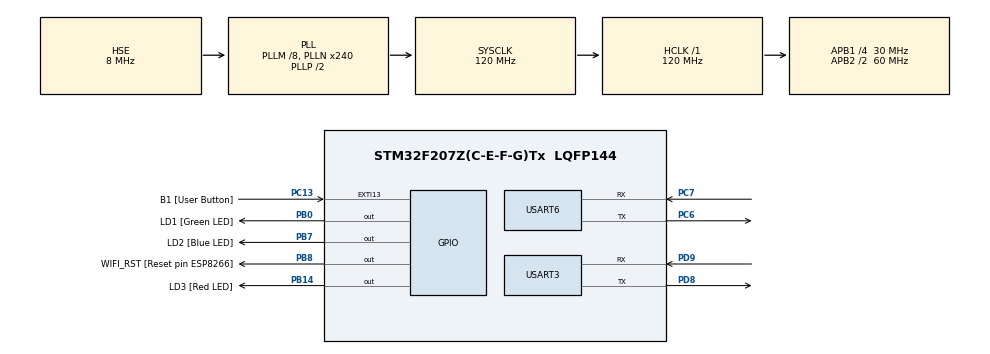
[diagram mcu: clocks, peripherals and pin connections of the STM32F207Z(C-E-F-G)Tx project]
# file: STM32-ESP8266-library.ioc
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FREERTOS.INCLUDE_vTaskCleanUpResources=1
FREERTOS.INCLUDE_vTaskDelayUntil=1
FREERTOS.Tasks01=DLMSThread,0,1280,DLMSThread_fun,Default,NULL,Dynamic,NULL,NULL
FREERTOS.configCHECK_FOR_STACK_OVERFLOW=1
FREERTOS.configMAX_PRIORITIES=8
FREERTOS.configTOTAL_HEAP_SIZE=65536
FREERTOS.configUSE_COUNTING_SEMAPHORES=1
FREERTOS.configUSE_MALLOC_FAILED_HOOK=1
FREERTOS.configUSE_NEWLIB_REENTRANT=1
FREERTOS.configUSE_RECURSIVE_MUTEXES=1
FREERTOS.configUSE_TIMERS=1
FREERTOS.configUSE_TRACE_FACILITY=1
Mcu.Family=STM32F2
Mcu.Name=STM32F207Z(C-E-F-G)Tx
Mcu.Package=LQFP144
Mcu.UserConstants=configMESSAGE_BUFFER_LENGTH_TYPE,size_t
NVIC.PriorityGroup=NVIC_PRIORITYGROUP_4
NVIC.TIM1_UP_TIM10_IRQn=true\:5\:0\:false\:false\:true\:false\:false\:true\:true
NVIC.TimeBase=TIM1_UP_TIM10_IRQn
NVIC.TimeBaseIP=TIM1
NVIC.USART3_IRQn=true\:5\:0\:true\:false\:true\:true\:true\:true\:true
NVIC.USART6_IRQn=true\:14\:0\:true\:false\:true\:true\:true\:true\:true
PA13.Mode=Serial_Wire
PA13.Signal=SYS_JTMS-SWDIO
PA14.Mode=Serial_Wire
PA14.Signal=SYS_JTCK-SWCLK
PB0.GPIO_Label=LD1 [Green LED]
PB0.Signal=GPIO_Output
PB14.GPIO_Label=LD3 [Red LED]
PB14.Signal=GPIO_Output
PB7.GPIO_Label=LD2 [Blue LED]
PB7.Signal=GPIO_Output
PB8.GPIO_Label=WIFI_RST [Reset pin ESP8266]
PB8.GPIO_PuPd=GPIO_PULLUP
PB8.PinState=GPIO_PIN_SET
PB8.Signal=GPIO_Output
PC13.GPIO_Label=B1 [User Button]
PC13.GPIO_ModeDefaultEXTI=GPIO_MODE_IT_FALLING
PC13.Signal=GPXTI13
PC14-OSC32_IN.Mode=LSE-External-Oscillator
PC14-OSC32_IN.Signal=RCC_OSC32_IN
PC15-OSC32_OUT.Mode=LSE-External-Oscillator
PC15-OSC32_OUT.Signal=RCC_OSC32_OUT
PC6.Mode=Asynchronous
PC6.Signal=USART6_TX
PC7.Mode=Asynchronous
PC7.Signal=USART6_RX
PD8.Mode=Asynchronous
PD8.Signal=USART3_TX
PD9.Mode=Asynchronous
PD9.Signal=USART3_RX
PH0-OSC_IN.Mode=HSE-External-Clock-Source
PH0-OSC_IN.Signal=RCC_OSC_IN
PH1-OSC_OUT.Mode=HSE-External-Clock-Source
PH1-OSC_OUT.Signal=RCC_OSC_OUT
ProjectManager.HeapSize=0x200
ProjectManager.StackSize=0x400
ProjectManager.TargetToolchain=STM32CubeIDE
RCC.48MHZClocksFreq_Value=48000000
RCC.AHBFreq_Value=120000000
RCC.APB1CLKDivider=RCC_HCLK_DIV4
RCC.APB1Freq_Value=30000000
RCC.APB1TimFreq_Value=60000000
RCC.APB2CLKDivider=RCC_HCLK_DIV2
RCC.APB2Freq_Value=60000000
RCC.APB2TimFreq_Value=120000000
RCC.CortexFreq_Value=120000000
RCC.HCLKFreq_Value=120000000
RCC.HSE_VALUE=8000000
RCC.HSI_VALUE=16000000
RCC.PLLM=8
RCC.PLLN=240
RCC.PLLQ=5
RCC.PLLSourceVirtual=RCC_PLLSOURCE_HSE
RCC.SYSCLKFreq_VALUE=120000000
RCC.SYSCLKSource=RCC_SYSCLKSOURCE_PLLCLK
RCC.VCOOutputFreq_Value=240000000
USART3.VirtualMode=VM_ASYNC
USART6.VirtualMode=VM_ASYNC
VP_FREERTOS_VS_CMSIS_V1.Mode=CMSIS_V1
VP_RNG_VS_RNG.Mode=RNG_Activate
VP_SYS_VS_tim1.Mode=TIM1
board=custom

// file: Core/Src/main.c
/* USER CODE BEGIN Header */
/**
  ******************************************************************************
  * @file           : main.c
  * @brief          : Main program body
  ******************************************************************************
  * @attention
  *
  * Copyright (c) 2022 STMicroelectronics.
  * All rights reserved.
  *
  * This software is licensed under terms that can be found in the LICENSE file
  * in the root directory of this software component.
  * If no LICENSE file comes with this software, it is provided AS-IS.
  *
  ******************************************************************************
  */
/* USER CODE END Header */
#include "main.h"
#include "cmsis_os.h"

/* USER CODE BEGIN Includes */
#include "STM32-Server.h"
#include "stdlib.h"
/* USER CODE END Includes */

/* USER CODE BEGIN PTD */
#ifndef max
#define max(a,b) (((a) > (b)) ? (a) : (b))
#define min(a,b) (((a) < (b)) ? (a) : (b))
#endif
/* USER CODE END PTD */

RNG_HandleTypeDef hrng;

UART_HandleTypeDef huart3;
UART_HandleTypeDef huart6;

osThreadId DLMSThreadHandle;

void SystemClock_Config(void);
static void MX_GPIO_Init(void);
static void MX_USART3_UART_Init(void);
static void MX_USART6_UART_Init(void);
static void MX_RNG_Init(void);
void DLMSThread_fun(void const * argument);

int main(void)
{

  /* MCU Configuration--------------------------------------------------------*/

  /* Reset of all peripherals, Initializes the Flash interface and the Systick. */
  HAL_Init();

  /* Configure the system clock */
  SystemClock_Config();

  /* Initialize all configured peripherals */
  MX_GPIO_Init();
  MX_USART3_UART_Init();
  MX_USART6_UART_Init();
  MX_RNG_Init();

  /* Create the thread(s) */
  /* definition and creation of DLMSThread */
  osThreadDef(DLMSThread, DLMSThread_fun, osPriorityNormal, 0, 1280);
  DLMSThreadHandle = osThreadCreate(osThread(DLMSThread), NULL);

  /* Start scheduler */
  osKernelStart();

  /* We should never get here as control is now taken by the scheduler */
  /* Infinite loop */
  while (1)
  {

  }
}

void SystemClock_Config(void)
{
  RCC_OscInitTypeDef RCC_OscInitStruct = {0};
  RCC_ClkInitTypeDef RCC_ClkInitStruct = {0};

  /** Initializes the RCC Oscillators according to the specified parameters
  * in the RCC_OscInitTypeDef structure.
  */
  RCC_OscInitStruct.OscillatorType = RCC_OSCILLATORTYPE_HSE;
  RCC_OscInitStruct.HSEState = RCC_HSE_BYPASS;
  RCC_OscInitStruct.PLL.PLLState = RCC_PLL_ON;
  RCC_OscInitStruct.PLL.PLLSource = RCC_PLLSOURCE_HSE;
  RCC_OscInitStruct.PLL.PLLM = 8;
  RCC_OscInitStruct.PLL.PLLN = 240;
  RCC_OscInitStruct.PLL.PLLP = RCC_PLLP_DIV2;
  RCC_OscInitStruct.PLL.PLLQ = 5;
  if (HAL_RCC_OscConfig(&RCC_OscInitStruct) != HAL_OK)
  {
    Error_Handler();
  }

  /** Initializes the CPU, AHB and APB buses clocks
  */
  RCC_ClkInitStruct.ClockType = RCC_CLOCKTYPE_HCLK|RCC_CLOCKTYPE_SYSCLK
                              |RCC_CLOCKTYPE_PCLK1|RCC_CLOCKTYPE_PCLK2;
  RCC_ClkInitStruct.SYSCLKSource = RCC_SYSCLKSOURCE_PLLCLK;
  RCC_ClkInitStruct.AHBCLKDivider = RCC_SYSCLK_DIV1;
  RCC_ClkInitStruct.APB1CLKDivider = RCC_HCLK_DIV4;
  RCC_ClkInitStruct.APB2CLKDivider = RCC_HCLK_DIV2;

  if (HAL_RCC_ClockConfig(&RCC_ClkInitStruct, FLASH_LATENCY_3) != HAL_OK)
  {
    Error_Handler();
  }
}

static void MX_RNG_Init(void)
{

  hrng.Instance = RNG;
  if (HAL_RNG_Init(&hrng) != HAL_OK)
  {
    Error_Handler();
  }

}

static void MX_USART3_UART_Init(void)
{

  huart3.Instance = USART3;
  huart3.Init.BaudRate = 115200;
  huart3.Init.WordLength = UART_WORDLENGTH_8B;
  huart3.Init.StopBits = UART_STOPBITS_1;
  huart3.Init.Parity = UART_PARITY_NONE;
  huart3.Init.Mode = UART_MODE_TX_RX;
  huart3.Init.HwFlowCtl = UART_HWCONTROL_NONE;
  huart3.Init.OverSampling = UART_OVERSAMPLING_16;
  if (HAL_UART_Init(&huart3) != HAL_OK)
  {
    Error_Handler();
  }

}

static void MX_USART6_UART_Init(void)
{

  huart6.Instance = USART6;
  huart6.Init.BaudRate = 115200;
  huart6.Init.WordLength = UART_WORDLENGTH_8B;
  huart6.Init.StopBits = UART_STOPBITS_1;
  huart6.Init.Parity = UART_PARITY_NONE;
  huart6.Init.Mode = UART_MODE_TX_RX;
  huart6.Init.HwFlowCtl = UART_HWCONTROL_NONE;
  huart6.Init.OverSampling = UART_OVERSAMPLING_16;
  if (HAL_UART_Init(&huart6) != HAL_OK)
  {
    Error_Handler();
  }

}

static void MX_GPIO_Init(void)
{
  GPIO_InitTypeDef GPIO_InitStruct = {0};

  /* GPIO Ports Clock Enable */
  __HAL_RCC_GPIOC_CLK_ENABLE();
  __HAL_RCC_GPIOH_CLK_ENABLE();
  __HAL_RCC_GPIOB_CLK_ENABLE();
  __HAL_RCC_GPIOD_CLK_ENABLE();
  __HAL_RCC_GPIOA_CLK_ENABLE();

  /*Configure GPIO pin Output Level */
  HAL_GPIO_WritePin(GPIOB, LD1_Pin|LD3_Pin|LD2_Pin, GPIO_PIN_RESET);

  /*Configure GPIO pin Output Level */
  HAL_GPIO_WritePin(WIFI_RST_GPIO_Port, WIFI_RST_Pin, GPIO_PIN_SET);

  /*Configure GPIO pin : B1_Pin */
  GPIO_InitStruct.Pin = B1_Pin;
  GPIO_InitStruct.Mode = GPIO_MODE_IT_FALLING;
  GPIO_InitStruct.Pull = GPIO_NOPULL;
  HAL_GPIO_Init(B1_GPIO_Port, &GPIO_InitStruct);

  /*Configure GPIO pins : LD1_Pin LD3_Pin LD2_Pin */
  GPIO_InitStruct.Pin = LD1_Pin|LD3_Pin|LD2_Pin;
  GPIO_InitStruct.Mode = GPIO_MODE_OUTPUT_PP;
  GPIO_InitStruct.Pull = GPIO_NOPULL;
  GPIO_InitStruct.Speed = GPIO_SPEED_FREQ_LOW;
  HAL_GPIO_Init(GPIOB, &GPIO_InitStruct);

  /*Configure GPIO pin : WIFI_RST_Pin */
  GPIO_InitStruct.Pin = WIFI_RST_Pin;
  GPIO_InitStruct.Mode = GPIO_MODE_OUTPUT_PP;
  GPIO_InitStruct.Pull = GPIO_PULLUP;
  GPIO_InitStruct.Speed = GPIO_SPEED_FREQ_LOW;
  HAL_GPIO_Init(WIFI_RST_GPIO_Port, &GPIO_InitStruct);

}

/* USER CODE BEGIN 4 */
void assert_failed(uint8_t* file, uint32_t line)
{
	while(1){};
}

void SysTick_Handler(void)
{
	osSystickHandler();
    HAL_IncTick();
}

/* USER CODE END 4 */

void DLMSThread_fun(void const * argument)
{
  /* USER CODE BEGIN 5 */
  (void) argument;
  RunServer();
  /* Infinite loop */
  for(;;);
  /* USER CODE END 5 */
}

void HAL_TIM_PeriodElapsedCallback(TIM_HandleTypeDef *htim)
{
  if (htim->Instance == TIM1) {
    HAL_IncTick();
  }
}

void Error_Handler(void)
{
  __disable_irq();
  while (1)
  {
  }
}

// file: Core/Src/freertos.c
/* USER CODE BEGIN Header */
/**
  ******************************************************************************
  * File Name          : freertos.c
  * Description        : Code for freertos applications
  ******************************************************************************
  * @attention
  *
  * Copyright (c) 2022 STMicroelectronics.
  * All rights reserved.
  *
  * This software is licensed under terms that can be found in the LICENSE file
  * in the root directory of this software component.
  * If no LICENSE file comes with this software, it is provided AS-IS.
  *
  ******************************************************************************
  */
/* USER CODE END Header */

#include "FreeRTOS.h"
#include "task.h"
#include "main.h"

/* GetIdleTaskMemory prototype (linked to static allocation support) */
void vApplicationGetIdleTaskMemory( StaticTask_t **ppxIdleTaskTCBBuffer, StackType_t **ppxIdleTaskStackBuffer, uint32_t *pulIdleTaskStackSize );

/* GetTimerTaskMemory prototype (linked to static allocation support) */
void vApplicationGetTimerTaskMemory( StaticTask_t **ppxTimerTaskTCBBuffer, StackType_t **ppxTimerTaskStackBuffer, uint32_t *pulTimerTaskStackSize );

/* Hook prototypes */
void vApplicationStackOverflowHook(xTaskHandle xTask, signed char *pcTaskName);
void vApplicationMallocFailedHook(void);

/* USER CODE BEGIN 4 */
__weak void vApplicationStackOverflowHook(xTaskHandle xTask, signed char *pcTaskName)
{
   /* Run time stack overflow checking is performed if
   configCHECK_FOR_STACK_OVERFLOW is defined to 1 or 2. This hook function is
   called if a stack overflow is detected. */
}
/* USER CODE END 4 */

/* USER CODE BEGIN 5 */
__weak void vApplicationMallocFailedHook(void)
{
   /* vApplicationMallocFailedHook() will only be called if
   configUSE_MALLOC_FAILED_HOOK is set to 1 in FreeRTOSConfig.h. It is a hook
   function that will get called if a call to pvPortMalloc() fails.
   pvPortMalloc() is called internally by the kernel whenever a task, queue,
   timer or semaphore is created. It is also called by various parts of the
   demo application. If heap_1.c or heap_2.c are used, then the size of the
   heap available to pvPortMalloc() is defined by configTOTAL_HEAP_SIZE in
   FreeRTOSConfig.h, and the xPortGetFreeHeapSize() API function can be used
   to query the size of free heap space that remains (although it does not
   provide information on how the remaining heap might be fragmented). */
}
/* USER CODE END 5 */

/* USER CODE BEGIN GET_IDLE_TASK_MEMORY */
static StaticTask_t xIdleTaskTCBBuffer;
static StackType_t xIdleStack[configMINIMAL_STACK_SIZE];

void vApplicationGetIdleTaskMemory( StaticTask_t **ppxIdleTaskTCBBuffer, StackType_t **ppxIdleTaskStackBuffer, uint32_t *pulIdleTaskStackSize )
{
  *ppxIdleTaskTCBBuffer = &xIdleTaskTCBBuffer;
  *ppxIdleTaskStackBuffer = &xIdleStack[0];
  *pulIdleTaskStackSize = configMINIMAL_STACK_SIZE;
  /* place for user code */
}
/* USER CODE END GET_IDLE_TASK_MEMORY */

/* USER CODE BEGIN GET_TIMER_TASK_MEMORY */
static StaticTask_t xTimerTaskTCBBuffer;
static StackType_t xTimerStack[configTIMER_TASK_STACK_DEPTH];

void vApplicationGetTimerTaskMemory( StaticTask_t **ppxTimerTaskTCBBuffer, StackType_t **ppxTimerTaskStackBuffer, uint32_t *pulTimerTaskStackSize )
{
  *ppxTimerTaskTCBBuffer = &xTimerTaskTCBBuffer;
  *ppxTimerTaskStackBuffer = &xTimerStack[0];
  *pulTimerTaskStackSize = configTIMER_TASK_STACK_DEPTH;
  /* place for user code */
}
/* USER CODE END GET_TIMER_TASK_MEMORY */
